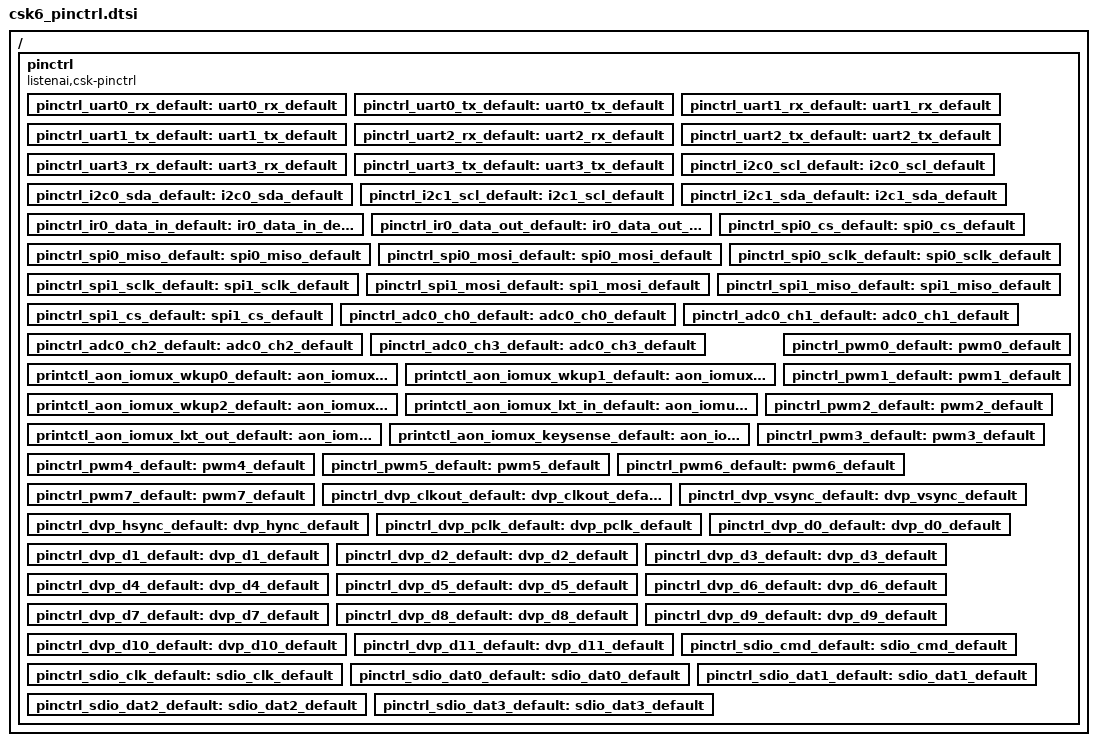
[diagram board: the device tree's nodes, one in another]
/* SPDX-License-Identifier: Apache-2.0 */

#include "csk6-pinctrl.h"

/ {
    pinctrl: pinctrl{
        compatible = "listenai,csk-pinctrl";

        /* UART alternate function */
        pinctrl_uart0_rx_default: uart0_rx_default{
        };

        pinctrl_uart0_tx_default: uart0_tx_default{
        };

        pinctrl_uart1_rx_default: uart1_rx_default{
        };

        pinctrl_uart1_tx_default: uart1_tx_default{
        };

        pinctrl_uart2_rx_default: uart2_rx_default{
        };

        pinctrl_uart2_tx_default: uart2_tx_default{
        };

        pinctrl_uart3_rx_default: uart3_rx_default{
        };

        pinctrl_uart3_tx_default: uart3_tx_default{
        };

        /* I2C alternate function */
        pinctrl_i2c0_scl_default: i2c0_scl_default{
        };

        pinctrl_i2c0_sda_default: i2c0_sda_default{
        };

        pinctrl_i2c1_scl_default: i2c1_scl_default{
        };

        pinctrl_i2c1_sda_default: i2c1_sda_default{
        };

        /* infrared alternate function */
        pinctrl_ir0_data_in_default: ir0_data_in_default{
        };
        pinctrl_ir0_data_out_default: ir0_data_out_default{
        };
        
        /* SPIC alternate function */
        pinctrl_spi0_cs_default: spi0_cs_default{
        };

        pinctrl_spi0_miso_default: spi0_miso_default{
        };

        pinctrl_spi0_mosi_default: spi0_mosi_default{
        };

        pinctrl_spi0_sclk_default: spi0_sclk_default{
        };

        pinctrl_spi1_sclk_default: spi1_sclk_default{
        };

        pinctrl_spi1_mosi_default: spi1_mosi_default{
        };

        pinctrl_spi1_miso_default: spi1_miso_default{
        };

        pinctrl_spi1_cs_default: spi1_cs_default{
        };

        /* ADC alternate function */
        pinctrl_adc0_ch0_default: adc0_ch0_default{
        };

        pinctrl_adc0_ch1_default: adc0_ch1_default{
        };

        pinctrl_adc0_ch2_default: adc0_ch2_default{
        };

        pinctrl_adc0_ch3_default: adc0_ch3_default{
        };

        /* AON_IOMUX (IO function configuration of the Always-ON domain)*/
        printctl_aon_iomux_wkup0_default: aon_iomux_wkup0_default {
        };
        printctl_aon_iomux_wkup1_default: aon_iomux_wkup1_default {
        };
        printctl_aon_iomux_wkup2_default: aon_iomux_wkup2_default {
        };
        printctl_aon_iomux_lxt_in_default: aon_iomux_lxt_in_default {
        };
        printctl_aon_iomux_lxt_out_default: aon_iomux_lxt_out_default {
        };
        printctl_aon_iomux_keysense_default: aon_iomux_keysense_default {
        };

        /* PWM alternate function*/
        pinctrl_pwm0_default: pwm0_default{
        };

        pinctrl_pwm1_default: pwm1_default{
        };

        pinctrl_pwm2_default: pwm2_default{
        };

        pinctrl_pwm3_default: pwm3_default{
        };

        pinctrl_pwm4_default: pwm4_default{
        };

        pinctrl_pwm5_default: pwm5_default{
        };

        pinctrl_pwm6_default: pwm6_default{
        };

        pinctrl_pwm7_default: pwm7_default{
        };

        /* DVP alternate function */
        pinctrl_dvp_clkout_default: dvp_clkout_default{
        };

        pinctrl_dvp_vsync_default: dvp_vsync_default{
        };

        pinctrl_dvp_hsync_default: dvp_hync_default{
        };

        pinctrl_dvp_pclk_default: dvp_pclk_default{
        };

        pinctrl_dvp_d0_default: dvp_d0_default{
        };

        pinctrl_dvp_d1_default: dvp_d1_default{
        };

        pinctrl_dvp_d2_default: dvp_d2_default{
        };

        pinctrl_dvp_d3_default: dvp_d3_default{
        };

        pinctrl_dvp_d4_default: dvp_d4_default{
        };

        pinctrl_dvp_d5_default: dvp_d5_default{
        };

        pinctrl_dvp_d6_default: dvp_d6_default{
        };

        pinctrl_dvp_d7_default: dvp_d7_default{
        };

        pinctrl_dvp_d8_default: dvp_d8_default{
        };

        pinctrl_dvp_d9_default: dvp_d9_default{
        };

        pinctrl_dvp_d10_default: dvp_d10_default{
        };

        pinctrl_dvp_d11_default: dvp_d11_default{
        };

        /* SDIO alternate function */
        pinctrl_sdio_cmd_default: sdio_cmd_default{
        };

        pinctrl_sdio_clk_default: sdio_clk_default{
        };

        pinctrl_sdio_dat0_default: sdio_dat0_default{
        };

        pinctrl_sdio_dat1_default: sdio_dat1_default{
        };

        pinctrl_sdio_dat2_default: sdio_dat2_default{
        };

        pinctrl_sdio_dat3_default: sdio_dat3_default{

        };

    };
};
